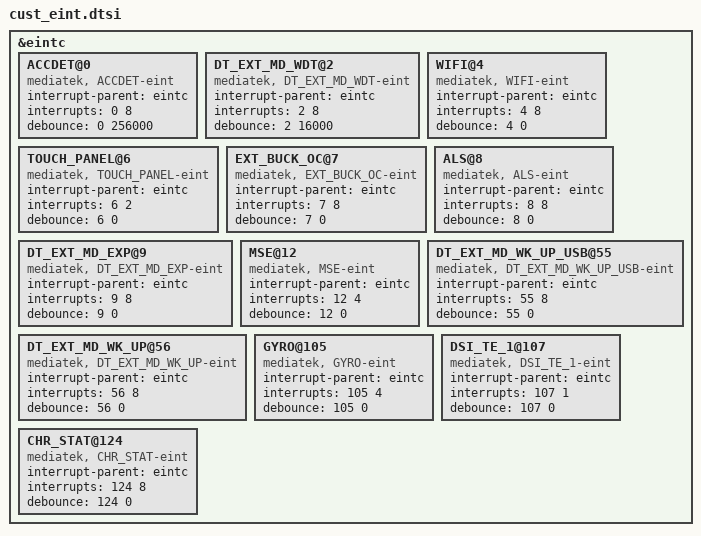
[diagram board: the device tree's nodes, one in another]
/*
 * Generated by MTK SP Drv_CodeGen Version 03.13.6  for MT6595. Copyright MediaTek Inc. (C) 2013.
 * Wed Apr 18 13:07:46 2018
 * Do Not Modify the File.
 */

/*************************
 * EINT DTSI File
*************************/

&eintc {
	ACCDET@0 {
		compatible = "mediatek, ACCDET-eint";
		interrupt-parent = <&eintc>;
		interrupts = <0 8>;
		debounce = <0 256000>;
	};

	DT_EXT_MD_WDT@2 {
		compatible = "mediatek, DT_EXT_MD_WDT-eint";
		interrupt-parent = <&eintc>;
		interrupts = <2 8>;
		debounce = <2 16000>;
	};

	WIFI@4 {
		compatible = "mediatek, WIFI-eint";
		interrupt-parent = <&eintc>;
		interrupts = <4 8>;
		debounce = <4 0>;
	};

	TOUCH_PANEL@6 {
		compatible = "mediatek, TOUCH_PANEL-eint";
		interrupt-parent = <&eintc>;
		interrupts = <6 2>;
		debounce = <6 0>;
	};

	EXT_BUCK_OC@7 {
		compatible = "mediatek, EXT_BUCK_OC-eint";
		interrupt-parent = <&eintc>;
		interrupts = <7 8>;
		debounce = <7 0>;
	};

	ALS@8 {
		compatible = "mediatek, ALS-eint";
		interrupt-parent = <&eintc>;
		interrupts = <8 8>;
		debounce = <8 0>;
	};

	DT_EXT_MD_EXP@9 {
		compatible = "mediatek, DT_EXT_MD_EXP-eint";
		interrupt-parent = <&eintc>;
		interrupts = <9 8>;
		debounce = <9 0>;
	};

	MSE@12 {
		compatible = "mediatek, MSE-eint";
		interrupt-parent = <&eintc>;
		interrupts = <12 4>;
		debounce = <12 0>;
	};

	DT_EXT_MD_WK_UP_USB@55 {
		compatible = "mediatek, DT_EXT_MD_WK_UP_USB-eint";
		interrupt-parent = <&eintc>;
		interrupts = <55 8>;
		debounce = <55 0>;
	};

	DT_EXT_MD_WK_UP@56 {
		compatible = "mediatek, DT_EXT_MD_WK_UP-eint";
		interrupt-parent = <&eintc>;
		interrupts = <56 8>;
		debounce = <56 0>;
	};

	GYRO@105 {
		compatible = "mediatek, GYRO-eint";
		interrupt-parent = <&eintc>;
		interrupts = <105 4>;
		debounce = <105 0>;
	};

	DSI_TE_1@107 {
		compatible = "mediatek, DSI_TE_1-eint";
		interrupt-parent = <&eintc>;
		interrupts = <107 1>;
		debounce = <107 0>;
	};

	CHR_STAT@124 {
		compatible = "mediatek, CHR_STAT-eint";
		interrupt-parent = <&eintc>;
		interrupts = <124 8>;
		debounce = <124 0>;
	};

};
